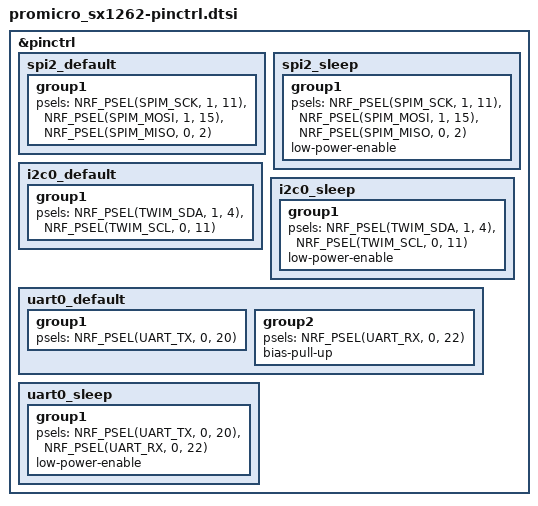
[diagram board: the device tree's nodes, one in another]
/*
 * ProMicro SX1262 pin control definitions
 * Copyright (c) 2025 ZephCore
 * SPDX-License-Identifier: MIT
 *
 * SPI2 (SX1262): SCK=P1.11, MOSI=P1.15, MISO=P0.02
 * I2C0 (sensors): SDA=P1.04, SCL=P0.11
 * UART0 (GPS):  TX=P0.20→GPS RX, RX=P0.22←GPS TX
 */

&pinctrl {
	spi2_default: spi2_default {
		group1 {
			psels = <NRF_PSEL(SPIM_SCK,  1, 11)>,
				<NRF_PSEL(SPIM_MOSI, 1, 15)>,
				<NRF_PSEL(SPIM_MISO, 0,  2)>;
		};
	};
	spi2_sleep: spi2_sleep {
		group1 {
			psels = <NRF_PSEL(SPIM_SCK,  1, 11)>,
				<NRF_PSEL(SPIM_MOSI, 1, 15)>,
				<NRF_PSEL(SPIM_MISO, 0,  2)>;
			low-power-enable;
		};
	};

	i2c0_default: i2c0_default {
		group1 {
			psels = <NRF_PSEL(TWIM_SDA, 1, 4)>,
				<NRF_PSEL(TWIM_SCL, 0, 11)>;
		};
	};
	i2c0_sleep: i2c0_sleep {
		group1 {
			psels = <NRF_PSEL(TWIM_SDA, 1, 4)>,
				<NRF_PSEL(TWIM_SCL, 0, 11)>;
			low-power-enable;
		};
	};

	uart0_default: uart0_default {
		group1 {
			psels = <NRF_PSEL(UART_TX, 0, 20)>;
		};
		group2 {
			psels = <NRF_PSEL(UART_RX, 0, 22)>;
			bias-pull-up;
		};
	};
	uart0_sleep: uart0_sleep {
		group1 {
			psels = <NRF_PSEL(UART_TX, 0, 20)>,
				<NRF_PSEL(UART_RX, 0, 22)>;
			low-power-enable;
		};
	};
};
